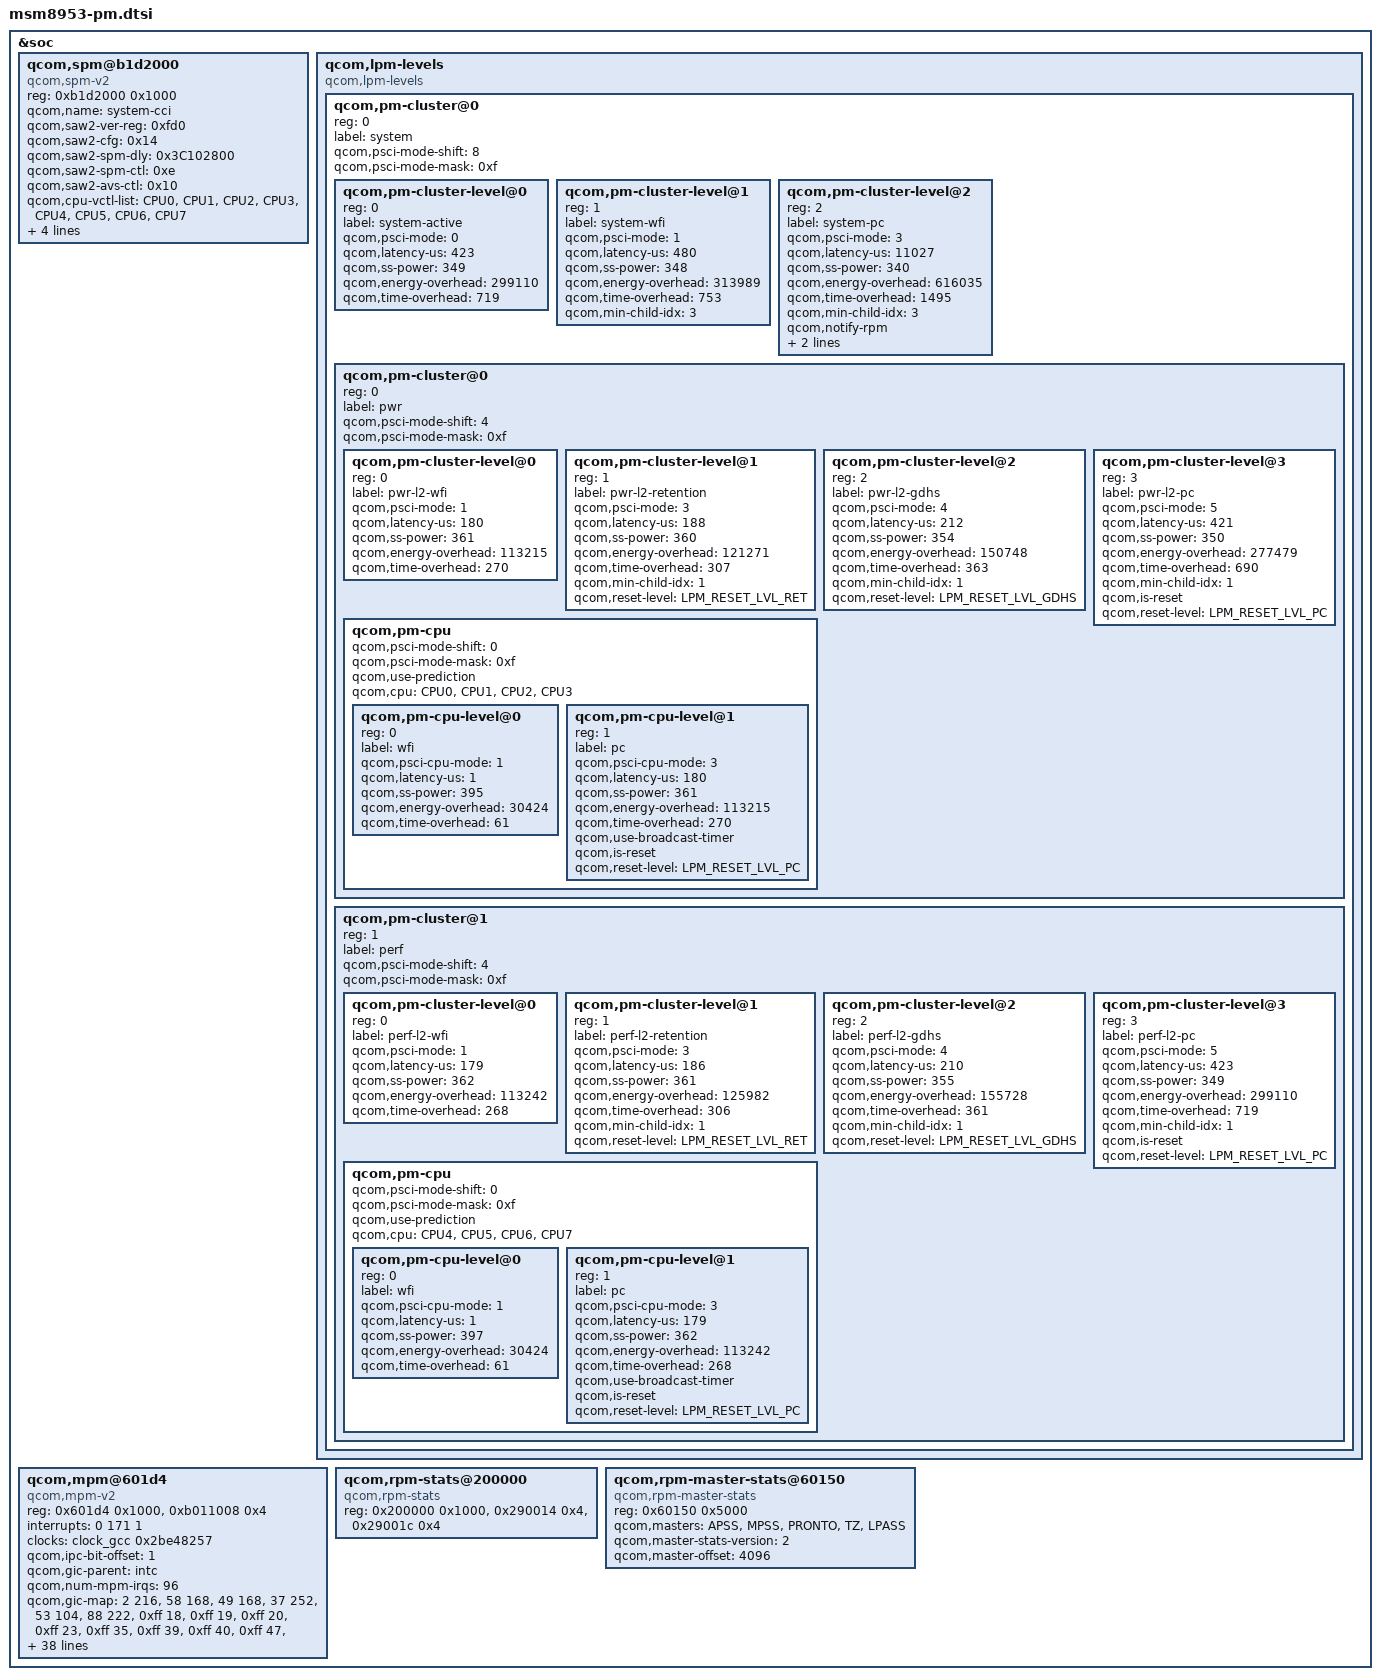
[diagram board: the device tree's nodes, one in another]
/* Copyright (c) 2015-2018, The Linux Foundation. All rights reserved.
 *
 * This program is free software; you can redistribute it and/or modify
 * it under the terms of the GNU General Public License version 2 and
 * only version 2 as published by the Free Software Foundation.
 *
 * This program is distributed in the hope that it will be useful,
 * but WITHOUT ANY WARRANTY; without even the implied warranty of
 * MERCHANTABILITY or FITNESS FOR A PARTICULAR PURPOSE.  See the
 * GNU General Public License for more details.
 */

#include <dt-bindings/msm/pm.h>

&soc {
	qcom,spm@b1d2000 {
		compatible = "qcom,spm-v2";
		#address-cells = <1>;
		#size-cells = <1>;
		reg = <0xb1d2000 0x1000>;
		reg-names = "saw-base";
		qcom,name = "system-cci";
		qcom,saw2-ver-reg = <0xfd0>;
		qcom,saw2-cfg = <0x14>;
		qcom,saw2-spm-dly= <0x3C102800>;
		qcom,saw2-spm-ctl = <0xe>;
		qcom,saw2-avs-ctl = <0x10>;
		qcom,cpu-vctl-list = <&CPU0 &CPU1 &CPU2 &CPU3
					&CPU4 &CPU5 &CPU6 &CPU7>;
		qcom,vctl-timeout-us = <500>;
		qcom,vctl-port = <0x0>;
		qcom,phase-port = <0x1>;
		qcom,pfm-port = <0x2>;
	};

	qcom,lpm-levels {
		compatible = "qcom,lpm-levels";
		#address-cells = <1>;
		#size-cells = <0>;

		qcom,pm-cluster@0 {
			reg = <0>;
			#address-cells = <1>;
			#size-cells = <0>;
			label = "system";
			qcom,psci-mode-shift = <8>;
			qcom,psci-mode-mask = <0xf>;

			qcom,pm-cluster-level@0 {
				reg = <0>;
				label = "system-active";
				qcom,psci-mode = <0>;
				qcom,latency-us = <423>;
				qcom,ss-power = <349>;
				qcom,energy-overhead = <299110>;
				qcom,time-overhead = <719>;
			};

			qcom,pm-cluster-level@1 {
				reg = <1>;
				label = "system-wfi";
				qcom,psci-mode = <1>;
				qcom,latency-us = <480>;
				qcom,ss-power = <348>;
				qcom,energy-overhead = <313989>;
				qcom,time-overhead = <753>;
				qcom,min-child-idx = <3>;
			};

			qcom,pm-cluster-level@2 {
				reg = <2>;
				label = "system-pc";
				qcom,psci-mode = <3>;
				qcom,latency-us = <11027>;
				qcom,ss-power = <340>;
				qcom,energy-overhead = <616035>;
				qcom,time-overhead = <1495>;
				qcom,min-child-idx = <3>;
				qcom,notify-rpm;
				qcom,is-reset;
				qcom,reset-level = <LPM_RESET_LVL_PC>;
			};

			qcom,pm-cluster@0{
				reg = <0>;
				#address-cells = <1>;
				#size-cells = <0>;
				label = "pwr";
				qcom,psci-mode-shift = <4>;
				qcom,psci-mode-mask = <0xf>;

				qcom,pm-cluster-level@0{
					reg = <0>;
					label = "pwr-l2-wfi";
					qcom,psci-mode = <1>;
					qcom,latency-us = <180>;
					qcom,ss-power = <361>;
					qcom,energy-overhead = <113215>;
					qcom,time-overhead = <270>;
				};

				qcom,pm-cluster-level@1{
					reg = <1>;
					label = "pwr-l2-retention";
					qcom,psci-mode = <3>;
					qcom,latency-us = <188>;
					qcom,ss-power = <360>;
					qcom,energy-overhead = <121271>;
					qcom,time-overhead = <307>;
					qcom,min-child-idx = <1>;
					qcom,reset-level =
						<LPM_RESET_LVL_RET>;
				};

				qcom,pm-cluster-level@2{
					reg = <2>;
					label = "pwr-l2-gdhs";
					qcom,psci-mode = <4>;
					qcom,latency-us = <212>;
					qcom,ss-power = <354>;
					qcom,energy-overhead = <150748>;
					qcom,time-overhead = <363>;
					qcom,min-child-idx = <1>;
					qcom,reset-level =
						<LPM_RESET_LVL_GDHS>;
				};

				qcom,pm-cluster-level@3{
					reg = <3>;
					label = "pwr-l2-pc";
					qcom,psci-mode = <5>;
					qcom,latency-us = <421>;
					qcom,ss-power = <350>;
					qcom,energy-overhead = <277479>;
					qcom,time-overhead = <690>;
					qcom,min-child-idx = <1>;
					qcom,is-reset;
					qcom,reset-level =
						<LPM_RESET_LVL_PC>;
				};

				qcom,pm-cpu {
					#address-cells = <1>;
					#size-cells = <0>;
					qcom,psci-mode-shift = <0>;
					qcom,psci-mode-mask = <0xf>;
					qcom,use-prediction;
					qcom,cpu = <&CPU0 &CPU1 &CPU2 &CPU3>;

					qcom,pm-cpu-level@0 {
						reg = <0>;
						label = "wfi";
						qcom,psci-cpu-mode = <1>;
						qcom,latency-us = <1>;
						qcom,ss-power = <395>;
						qcom,energy-overhead = <30424>;
						qcom,time-overhead = <61>;
					};

					qcom,pm-cpu-level@1 {
						reg = <1>;
						label = "pc";
						qcom,psci-cpu-mode = <3>;
						qcom,latency-us = <180>;
						qcom,ss-power = <361>;
						qcom,energy-overhead = <113215>;
						qcom,time-overhead = <270>;
						qcom,use-broadcast-timer;
						qcom,is-reset;
						qcom,reset-level =
							<LPM_RESET_LVL_PC>;
					};
				};
			};

			qcom,pm-cluster@1{
				reg = <1>;
				#address-cells = <1>;
				#size-cells = <0>;
				label = "perf";
				qcom,psci-mode-shift = <4>;
				qcom,psci-mode-mask = <0xf>;

				qcom,pm-cluster-level@0{
					reg = <0>;
					label = "perf-l2-wfi";
					qcom,psci-mode = <1>;
					qcom,latency-us = <179>;
					qcom,ss-power = <362>;
					qcom,energy-overhead = <113242>;
					qcom,time-overhead = <268>;
				};

				qcom,pm-cluster-level@1{
					reg = <1>;
					label = "perf-l2-retention";
					qcom,psci-mode = <3>;
					qcom,latency-us = <186>;
					qcom,ss-power = <361>;
					qcom,energy-overhead = <125982>;
					qcom,time-overhead = <306>;
					qcom,min-child-idx = <1>;
					qcom,reset-level =
						<LPM_RESET_LVL_RET>;
				};

				qcom,pm-cluster-level@2{
					reg = <2>;
					label = "perf-l2-gdhs";
					qcom,psci-mode = <4>;
					qcom,latency-us = <210>;
					qcom,ss-power = <355>;
					qcom,energy-overhead = <155728>;
					qcom,time-overhead = <361>;
					qcom,min-child-idx = <1>;
					qcom,reset-level =
						<LPM_RESET_LVL_GDHS>;
				};

				qcom,pm-cluster-level@3{
					reg = <3>;
					label = "perf-l2-pc";
					qcom,psci-mode = <5>;
					qcom,latency-us = <423>;
					qcom,ss-power = <349>;
					qcom,energy-overhead = <299110>;
					qcom,time-overhead = <719>;
					qcom,min-child-idx = <1>;
					qcom,is-reset;
					qcom,reset-level =
						<LPM_RESET_LVL_PC>;
				};

				qcom,pm-cpu {
					#address-cells = <1>;
					#size-cells = <0>;
					qcom,psci-mode-shift = <0>;
					qcom,psci-mode-mask = <0xf>;
					qcom,use-prediction;
					qcom,cpu = <&CPU4 &CPU5 &CPU6 &CPU7>;

					qcom,pm-cpu-level@0 {
						reg = <0>;
						label = "wfi";
						qcom,psci-cpu-mode = <1>;
						qcom,latency-us = <1>;
						qcom,ss-power = <397>;
						qcom,energy-overhead = <30424>;
						qcom,time-overhead = <61>;
					};

					qcom,pm-cpu-level@1 {
						reg = <1>;
						label = "pc";
						qcom,psci-cpu-mode = <3>;
						qcom,latency-us = <179>;
						qcom,ss-power = <362>;
						qcom,energy-overhead = <113242>;
						qcom,time-overhead = <268>;
						qcom,use-broadcast-timer;
						qcom,is-reset;
						qcom,reset-level =
							<LPM_RESET_LVL_PC>;
					};
				};
			};
		};
	};

	qcom,mpm@601d4 {
		compatible = "qcom,mpm-v2";
		reg = <0x601d4 0x1000>,
			<0xb011008 0x4>;
		reg-names = "vmpm", "ipc";
		interrupts = <0 171 1>;
		clocks = <&clock_gcc 0x2be48257>;
		clock-names = "xo";
		qcom,ipc-bit-offset = <1>;
		qcom,gic-parent = <&intc>;
		qcom,num-mpm-irqs = <96>;
		qcom,gic-map = <2 216>,
		<58 168>,
		<49 168>,
		<37 252>,
		<53 104>,
		<88 222>,
		<0xff 18>,
		<0xff 19>,
		<0xff 20>,
		<0xff 23>,
		<0xff 35>,
		<0xff 39>,
		<0xff 40>,
		<0xff 47>,
		<0xff 54>,
		<0xff 56>,
		<0xff 57>,
		<0xff 58>,
		<0xff 59>,
		<0xff 60>,
		<0xff 61>,
		<0xff 65>,
		<0xff 69>,
		<0xff 73>,
		<0xff 74>,
		<0xff 75>,
		<0xff 78>,
		<0xff 79>,
		<0xff 85>,
		<0xff 86>,
		<0xff 90>,
		<0xff 92>,
		<0xff 93>,
		<0xff 97>,
		<0xff 102>,
		<0xff 108>,
		<0xff 109>,
		<0xff 112>,
		<0xff 114>,
		<0xff 126>,
		<0xff 128>,
		<0xff 131>,
		<0xff 136>,
		<0xff 137>,
		<0xff 138>,
		<0xff 139>,
		<0xff 140>,
		<0xff 141>,
		<0xff 142>,
		<0xff 143>,
		<0xff 144>,
		<0xff 145>,
		<0xff 146>,
		<0xff 147>,
		<0xff 148>,
		<0xff 149>,
		<0xff 150>,
		<0xff 151>,
		<0xff 152>,
		<0xff 153>,
		<0xff 155>,
		<0xff 157>,
		<0xff 166>,
		<0xff 167>,
		<0xff 170>,
		<0xff 172>,
		<0xff 173>,
		<0xff 174>,
		<0xff 175>,
		<0xff 176>,
		<0xff 177>,
		<0xff 178>,
		<0xff 179>,
		<0xff 181>,
		<0xff 188>,
		<0xff 189>,
		<0xff 190>,
		<0xff 191>,
		<0xff 192>,
		<0xff 193>,
		<0xff 194>,
		<0xff 195>,
		<0xff 196>,
		<0xff 197>,
		<0xff 198>,
		<0xff 200>,
		<0xff 201>,
		<0xff 202>,
		<0xff 203>,
		<0xff 204>,
		<0xff 205>,
		<0xff 206>,
		<0xff 207>,
		<0xff 212>,
		<0xff 215>,
		<0xff 224>,
		<0xff 231>,
		<0xff 239>,
		<0xff 240>,
		<0xff 253>,
		<0xff 257>,
		<0xff 260>,
		<0xff 262>,
		<0xff 263>,
		<0xff 264>,
		<0xff 269>,
		<0xff 270>,
		<0xff 273>,
		<0xff 274>,
		<0xff 275>,
		<0xff 276>,
		<0xff 285>,
		<0xff 286>,
		<0xff 287>,
		<0xff 305>,
		<0xff 306>,
		<0xff 307>,
		<0xff 308>,
		<0xff 314>,
		<0xff 321>,
		<0xff 322>,
		<0xff 323>,
		<0xff 325>,
		<0xff 344>,
		<0xff 346>;

		qcom,gpio-parent = <&tlmm>;
		qcom,gpio-map = <3 38 >,
		<4 1 >,
		<5 5 >,
		<6 9 >,
		<8 37>,
		<9 36>,
		<10 13>,
		<11 35>,
		<12 17>,
		<13 21>,
		<14 54>,
		<15 34>,
		<16 31>,
		<17 58>,
		<18 28>,
		<19 42>,
		<20 25>,
		<21 12>,
		<22 43>,
		<23 44>,
		<24 45>,
		<25 46>,
		<26 48>,
		<27 65>,
		<28 93>,
		<29 97>,
		<30 63>,
		<31 70>,
		<32 71>,
		<33 72>,
		<34 81>,
		<35 85>,
		<36 90>,
		<50 67>,
		<51 73>,
		<52 74>,
		<53 62>,
		<59 59>,
		<60 60>,
		<61 61>,
		<62 86>,
		<63 87>,
		<64 91>,
		<65 129>,
		<66 130>,
		<67 131>,
		<68 132>,
		<69 133>,
		<70 137>,
		<71 138>,
		<72 139>,
		<73 140>,
		<74 141>,
		<0xff 88>;
	};

	qcom,rpm-stats@200000 {
		compatible = "qcom,rpm-stats";
		reg = <0x200000 0x1000>, <0x290014 0x4>, <0x29001c 0x4>;
		reg-names = "phys_addr_base", "offset_addr";
	};

	qcom,rpm-master-stats@60150 {
		compatible = "qcom,rpm-master-stats";
		reg = <0x60150 0x5000>;
		qcom,masters = "APSS", "MPSS", "PRONTO", "TZ", "LPASS";
		qcom,master-stats-version = <2>;
		qcom,master-offset = <4096>;
	};

};
